# AT90USB162 register map
Vendor: Atmel; File version: 1.0
CPU: other r0p0, little endian, no MPU, no FPU, 4 interrupt priority bits
Registers are 8-bit, read-write, reset 0x0 unless marked. A register's access mark holds for its fields unless they carry their own. Offsets are from the block's base; [hi:lo] are bit positions.

## TC0 — Timer/Counter, 8-bit
Base 0x00800035
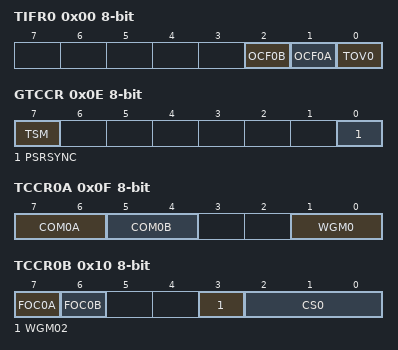
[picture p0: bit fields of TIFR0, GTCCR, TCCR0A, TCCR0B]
0x00 TIFR0 — Timer/Counter0 Interrupt Flag register (read-only for debugger)
  [2] OCF0B — Timer/Counter0 Output Compare Flag 0B
  [1] OCF0A — Timer/Counter0 Output Compare Flag 0A
  [0] TOV0 — Timer/Counter0 Overflow Flag
0x0E GTCCR — General Timer/Counter Control Register
  [7] TSM — Timer/Counter Synchronization Mode
  [0] PSRSYNC — Prescaler Reset Timer/Counter1 and Timer/Counter0
0x0F TCCR0A — Timer/Counter Control Register A
  [7:6] COM0A — Compare Output Mode, Phase Correct PWM Mode
  [5:4] COM0B — Compare Output Mode, Fast PWm
  [1:0] WGM0 — Waveform Generation Mode
0x10 TCCR0B — Timer/Counter Control Register B
  [7] FOC0A — Force Output Compare A
  [6] FOC0B — Force Output Compare B
  [3] WGM02
  [2:0] CS0 — Clock Select
    0=NO_CLOCK_SOURCE_STOPPED; 1=RUNNING_NO_PRESCALING; 2=RUNNING_CLK_8; 3=RUNNING_CLK_64; 4=RUNNING_CLK_256; 5=RUNNING_CLK_1024; 6=RUNNING_EXTCLK_TN_FALLING_EDGE; 7=RUNNING_EXTCLK_TN_RISING_EDGE
0x11 TCNT0 — Timer/Counter0
0x12 OCR0A — Timer/Counter0 Output Compare Register
0x13 OCR0B — Timer/Counter0 Output Compare Register
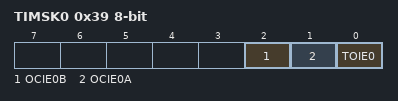
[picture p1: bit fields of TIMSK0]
0x39 TIMSK0 — Timer/Counter0 Interrupt Mask Register
  [2] OCIE0B — Timer/Counter0 Output Compare Match B Interrupt Enable
  [1] OCIE0A — Timer/Counter0 Output Compare Match A Interrupt Enable
  [0] TOIE0 — Timer/Counter0 Overflow Interrupt Enable

## TC1 — Timer/Counter, 16-bit
Base 0x00800036
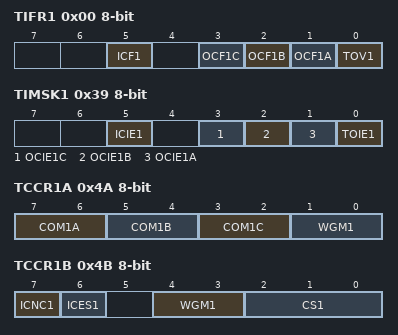
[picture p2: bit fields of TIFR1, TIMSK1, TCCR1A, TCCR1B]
0x00 TIFR1 — Timer/Counter1 Interrupt Flag register (read-only for debugger)
  [5] ICF1 — Input Capture Flag 1
  [3] OCF1C — Output Compare Flag 1C
  [2] OCF1B — Output Compare Flag 1B
  [1] OCF1A — Output Compare Flag 1A
  [0] TOV1 — Timer/Counter1 Overflow Flag
0x39 TIMSK1 — Timer/Counter1 Interrupt Mask Register
  [5] ICIE1 — Timer/Counter1 Input Capture Interrupt Enable
  [3] OCIE1C — Timer/Counter1 Output Compare C Match Interrupt Enable
  [2] OCIE1B — Timer/Counter1 Output Compare B Match Interrupt Enable
  [1] OCIE1A — Timer/Counter1 Output Compare A Match Interrupt Enable
  [0] TOIE1 — Timer/Counter1 Overflow Interrupt Enable
0x4A TCCR1A — Timer/Counter1 Control Register A
  [7:6] COM1A — Compare Output Mode 1A, bits
  [5:4] COM1B — Compare Output Mode 1B, bits
  [3:2] COM1C — Compare Output Mode 1C, bits
  [1:0] WGM1 — Waveform Generation Mode
0x4B TCCR1B — Timer/Counter1 Control Register B
  [7] ICNC1 — Input Capture 1 Noise Canceler
  [6] ICES1 — Input Capture 1 Edge Select
  [4:3] WGM1 — Waveform Generation Mode
  [2:0] CS1 — Prescaler source of Timer/Counter 1
    0=NO_CLOCK_SOURCE_STOPPED; 1=RUNNING_NO_PRESCALING; 2=RUNNING_CLK_8; 3=RUNNING_CLK_64; 4=RUNNING_CLK_256; 5=RUNNING_CLK_1024; 6=RUNNING_EXTCLK_TN_FALLING_EDGE; 7=RUNNING_EXTCLK_TN_RISING_EDGE
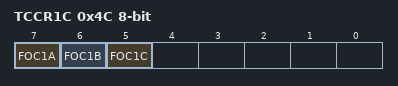
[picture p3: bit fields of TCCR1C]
0x4C TCCR1C — Timer/Counter 1 Control Register C
  [7] FOC1A — Force Output Compare 1A
  [6] FOC1B — Force Output Compare 1B
  [5] FOC1C — Force Output Compare 1C
0x4E TCNT1 16-bit (reset mask 0xFF) — Timer/Counter1 Bytes
0x50 ICR1 16-bit (reset mask 0xFF) — Timer/Counter1 Input Capture Register Bytes
0x52 OCR1A 16-bit (reset mask 0xFF) — Timer/Counter1 Output Compare Register A Bytes
0x54 OCR1B 16-bit (reset mask 0xFF) — Timer/Counter1 Output Compare Register B Bytes
0x56 OCR1C 16-bit (reset mask 0xFF) — Timer/Counter1 Output Compare Register C Bytes

## USART1 — USART
Base 0x008000C8
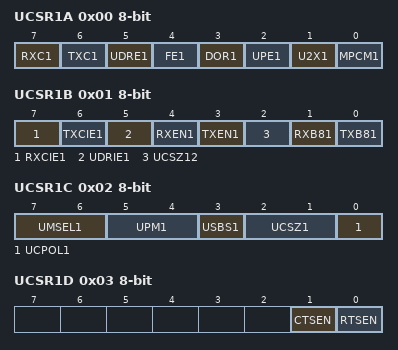
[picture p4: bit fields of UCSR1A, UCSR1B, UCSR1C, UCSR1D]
0x00 UCSR1A — USART Control and Status Register A
  [7] RXC1 — USART Receive Complete
  [6] TXC1 — USART Transmit Complete
  [5] UDRE1 — USART Data Register Empty
  [4] FE1 — Framing Error
  [3] DOR1 — Data overRun
  [2] UPE1 — Parity Error
  [1] U2X1 — Double the USART transmission speed
  [0] MPCM1 — Multi-processor Communication Mode
0x01 UCSR1B — USART Control and Status Register B
  [7] RXCIE1 — RX Complete Interrupt Enable
  [6] TXCIE1 — TX Complete Interrupt Enable
  [5] UDRIE1 — USART Data register Empty Interrupt Enable
  [4] RXEN1 — Receiver Enable
  [3] TXEN1 — Transmitter Enable
  [2] UCSZ12 — Character Size
  [1] RXB81 — Receive Data Bit 8
  [0] TXB81 — Transmit Data Bit 8
0x02 UCSR1C — USART Control and Status Register C
  [7:6] UMSEL1 — USART Mode Select
  [5:4] UPM1 — Parity Mode Bits
  [3] USBS1 — Stop Bit Select
  [2:1] UCSZ1 — Character Size
  [0] UCPOL1 — Clock Polarity
0x03 UCSR1D — USART Control and Status Register D
  [1] CTSEN — CTS Enable
  [0] RTSEN — RTS Enable
0x04 UBRR1 16-bit (reset mask 0xFF) — USART Baud Rate Register Bytes
0x06 UDR1 — USART I/O Data Register

## USB_DEVICE — USB Device Registers
Base 0x00800063
0x00 REGCR — Regulator Control Register (read-only for debugger)
  [0] REGDIS
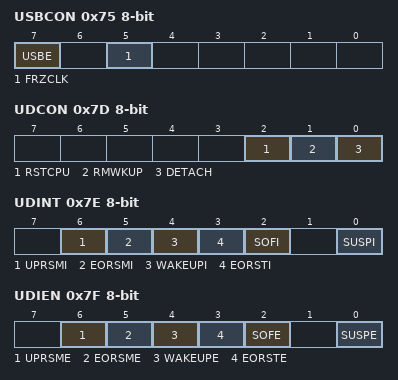
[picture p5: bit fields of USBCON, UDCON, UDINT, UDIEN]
0x75 USBCON — USB General Control Register
  [7] USBE, [5] FRZCLK
0x7D UDCON
  [2] RSTCPU, [1] RMWKUP, [0] DETACH
0x7E UDINT
  [6] UPRSMI, [5] EORSMI, [4] WAKEUPI, [3] EORSTI, [2] SOFI, [0] SUSPI
0x7F UDIEN
  [6] UPRSME, [5] EORSME, [4] WAKEUPE, [3] EORSTE, [2] SOFE, [0] SUSPE
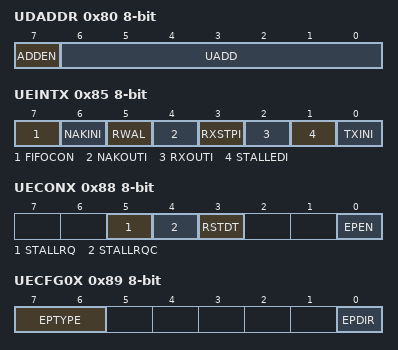
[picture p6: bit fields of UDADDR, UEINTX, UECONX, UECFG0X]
0x80 UDADDR
  [7] ADDEN, [6:0] UADD
0x81 UDFNUM 16-bit (reset mask 0xFF)
0x83 UDMFN
  [4] FNCERR
0x85 UEINTX
  [7] FIFOCON, [6] NAKINI, [5] RWAL, [4] NAKOUTI, [3] RXSTPI, [2] RXOUTI, [1] STALLEDI, [0] TXINI
0x86 UENUM
0x87 UERST
  [4:0] EPRST
0x88 UECONX
  [5] STALLRQ, [4] STALLRQC, [3] RSTDT, [0] EPEN
0x89 UECFG0X
  [7:6] EPTYPE, [0] EPDIR
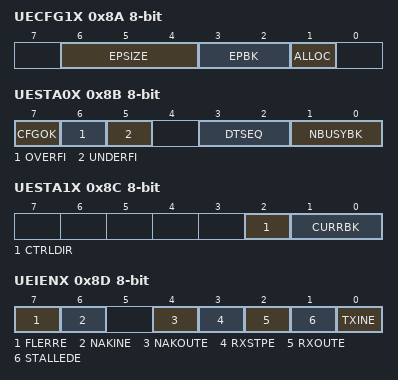
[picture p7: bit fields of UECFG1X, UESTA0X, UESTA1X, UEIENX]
0x8A UECFG1X
  [6:4] EPSIZE, [3:2] EPBK, [1] ALLOC
0x8B UESTA0X
  [7] CFGOK, [6] OVERFI, [5] UNDERFI, [3:2] DTSEQ, [1:0] NBUSYBK
0x8C UESTA1X
  [2] CTRLDIR, [1:0] CURRBK
0x8D UEIENX
  [7] FLERRE, [6] NAKINE, [4] NAKOUTE, [3] RXSTPE, [2] RXOUTE, [1] STALLEDE, [0] TXINE
0x8E UEDATX
0x8F UEBCLX
0x91 UEINT

## WDT — Watchdog Timer
Base 0x00800060
0x00 WDTCSR — Watchdog Timer Control Register (read-only for debugger)
  [7] WDIF — Watchdog Timeout Interrupt Flag
  [6] WDIE — Watchdog Timeout Interrupt Enable
  [4] WDCE — Watchdog Change Enable
  [3] WDE — Watch Dog Enable
  [5:0] WDP — Watchdog Timer Prescaler Bits
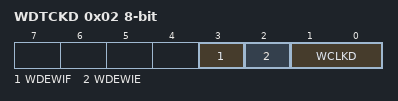
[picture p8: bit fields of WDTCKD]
0x02 WDTCKD — Watchdog Timer Clock Divider
  [3] WDEWIF — Watchdog Early Warning Interrupt Flag
  [2] WDEWIE — Watchdog Early Warning Interrupt Enable
  [1:0] WCLKD — Watchdog Timer Clock Dividers
